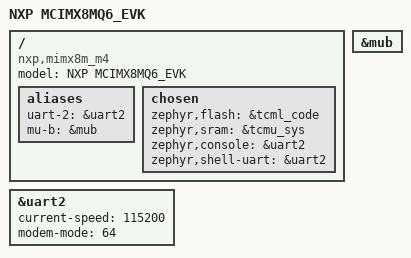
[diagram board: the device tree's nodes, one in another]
/*
 * Copyright (c) 2019, Prevas A/S
 *
 * SPDX-License-Identifier: Apache-2.0
 */

/dts-v1/;

#include <nxp/nxp_imx8m_m4.dtsi>

/ {
	model = "NXP MCIMX8MQ6_EVK";
	compatible = "nxp,mimx8m_m4";

	aliases {
		uart-2 = &uart2;
		mu-b   = &mub;
	};

	chosen {
		zephyr,flash = &tcml_code;
		zephyr,sram = &tcmu_sys;
		zephyr,console = &uart2;
		zephyr,shell-uart = &uart2;
	};

};

&uart2 {
	status = "okay";
	current-speed = <115200>;
	modem-mode = <64>;
};

&mub {
	status = "okay";
};
